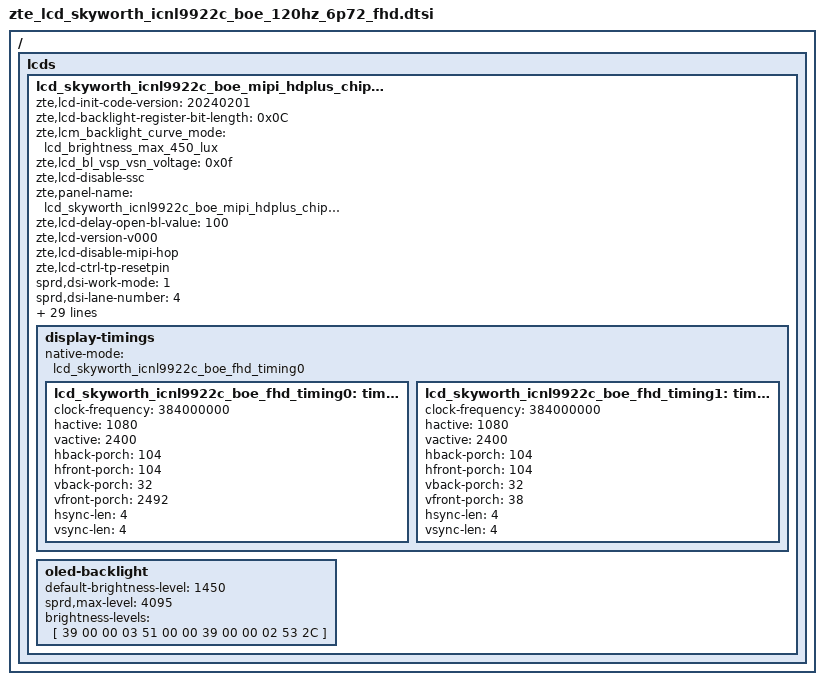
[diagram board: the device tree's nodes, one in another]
/ {
	fragment {
		target-path = "/";
		__overlay__ {
			lcds {
				lcd_skyworth_icnl9922c_boe_mipi_hdplus_chipone: lcd_skyworth_icnl9922c_boe_mipi_hdplus_chipone {
					zte,lcd-init-code-version = "20240201";

					zte,lcd-backlight-register-bit-length = <0x0C>;
					zte,lcm_backlight_curve_mode = "lcd_brightness_max_450_lux";
					zte,lcd_bl_vsp_vsn_voltage = <0x0f>;
					zte,lcd-disable-ssc;
					zte,panel-name = "lcd_skyworth_icnl9922c_boe_mipi_hdplus_chipone";
					zte,lcd-delay-open-bl-value = <100>;
					zte,lcd-version-v000;
					zte,lcd-disable-mipi-hop;
					zte,lcd-ctrl-tp-resetpin;

					sprd,dsi-work-mode = <1>;
					sprd,dsi-lane-number = <4>;
					sprd,dsi-color-format = "dsc";
					sprd,phy-bit-clock = <1100000>;
					sprd,phy-escape-clock = <20000>;/* kHz */

					sprd,width-mm = <70081>;
					sprd,height-mm = <155736>;
					sprd,vrr-enabled;
					sprd,vrr-max-layers = <3>;
					sprd,slice-width = <540>;
					sprd,slice-height = <8>;
					sprd,output-bpc = <8>;
					sprd,dsc-enable = <1>;
					sprd,dual-dsi-enable = <0>;

					sprd,esd-check-enable = <1>;/* 0:close , 1:open */
					sprd,esd-check-mode = <1>;/* 0:REG ,1:TE  */
					sprd,esd-check-period = <2000>;
					sprd,esd-check-register = <0x0A>;
					sprd,esd-check-value = <0x9C>;

					sprd,dphy-taget-val = <5>;

					sprd,reset-on-sequence = <1 5>, <0 15>, <1 25>;
					sprd,reset-off-sequence = <1 20>;

					sprd,use-gen-write;
					sprd,initial-command = [
39 00 00 04 F0 99 22 0C
39 00 00 10 70 C1 12 00 05 00 5A 00 6F 00 77 00 31 02 00 20
39 00 00 21 71 11 00 00 89 30 80 09 60 04 38 00 08 02 1C 02 1C 02 00 02 0E 00 20 00 BB 00 07 00 0C 0D B7 0C B7
39 00 00 21 72 18 00 10 F0 03 0C 20 00 06 0B 0B 33 0E 1C 2A 38 46 54 62 69 70 77 79 7B 7D 7E 01 02 01 00 09 40
39 00 00 19 73 09 BE 19 FC 19 FA 19 F8 1A 38 1A 78 1A B6 2A F6 2B 34 2B 74 3B 74 6B F4
39 00 00 1C C7 77 77 77 77 77 77 77 77 10 77 77 77 77 77 77 77 77 10 34 00 01 FF FF 00 F0 F0 00
39 00 00 21 80 FF F6 E8 DE D5 CE C8 C3 BE AE A2 99 91 89 83 79 6F 67 5F 5F 57 50 47 3F 39 34 2D 26 1D 11 0F 0D
39 00 00 21 81 FF F6 E8 DE D5 CE C8 C3 BE AE A2 99 91 89 83 79 6F 67 5F 5F 57 50 47 3F 39 34 2D 26 1D 11 0F 0D
39 00 00 21 82 FF F6 E8 DE D5 CE C8 C3 BE AE A2 99 91 89 83 79 6F 67 5F 5F 57 50 47 3F 39 34 2D 26 1D 11 0F 0D
39 00 00 21 83 09 0C 0A 08 05 03 02 0C 0A 08 05 03 02 0C 0A 08 05 03 02 12 0E 0A 06 02 00 12 0E 0A 06 02 00 12
39 00 00 21 84 0E 0A 06 02 00 04 E8 FC 3C E9 CC C8 37 02 30 4E 8F C3 CE 9C CC 83 70 23 04 E8 FC 3C E9 CC C8 37
39 00 00 1F 85 02 30 00 00 00 00 00 00 00 00 00 00 00 00 00 00 00 00 00 00 00 00 00 00 00 00 00 00 00 00
39 00 00 21 B2 0D 06 05 04 F2 22 03 00 22 00 00 00 00 00 00 00 00 63 5D 00 00 00 00 00 00 55 55 05 05 00 00 00
39 00 00 21 B3 31 0B 01 0B 81 63 00 00 5D 00 00 00 00 00 00 03 FC C0 00 C0 00 00 00 00 00 00 FF FF FF FF FF FF
39 00 00 21 B4 30 04 01 05 81 02 00 00 47 00 00 00 00 00 00 03 FC C0 00 C0 00 00 00 00 00 00 FF FF FF FF FF FF
39 00 00 21 B5 00 0B 06 0D 10 26 34 91 A2 33 44 00 26 00 BF 3C 02 08 20 30 00 00 00 00 00 00 00 00 00 00 5C 35
39 00 00 21 B6 82 82 82 1E 1D 1C 82 0D 0C 0F 0E 82 3A 3A 82 C0 82 00 00 00 28 05 04 01 FF FF FF 00 00 00 3C 00
39 00 00 21 B7 82 82 82 1E 1D 1C 82 0D 0C 0F 0E 82 3A 3A 82 C0 82 00 00 00 28 05 04 01 FF FF FF 00 00 00 3C 00
39 00 00 21 B8 03 01 01 82 00 80 00 00 00 00 1F 00 00 00 00 00 00 00 00 00 00 00 00 00 00 00 00 00 00 00 00 00
39 00 00 21 9D 00 00 00 12 1D 39 44 5E 54 61 6B 79 83 92 00 00 00 00 00 00 00 00 00 00 00 00 00 00 00 00 00 00
39 00 00 21 B9 12 33 21 12 33 21 12 33 21 12 33 21 12 33 21 12 33 21 12 33 21 12 33 21 00 00 00 00 00 00 00 02
39 00 00 1A BA 01 AB FB FE FB BF FF AB FB FE FB BF FF AB F8 02 0B 80 00 AB F8 02 0B 80 00
39 00 00 0F BB 01 02 03 0A 04 13 14 52 16 5C 00 15 16 00
39 00 00 21 BC 00 00 00 00 04 00 FF F8 0B 11 50 5E 55 99 00 00 00 00 00 00 00 00 00 00 00 00 00 00 00 00 00 00
39 00 00 0D BD A1 A2 52 2E 00 8F 0D 09 C1 04 01 AE
39 00 00 0D BE 28 1E 0B AA 43 35 33 32 1E 00 00 3A
39 00 00 17 C0 40 93 FF FF FF 3F FF 00 FF 00 CC 04 12 35 67 89 A0 FF FF F0 0B EB
39 00 00 16 C1 00 00 20 26 26 04 68 68 04 60 19 22 50 01 11 07 69 A0 A0 00 93
15 00 00 02 C2 00
39 00 00 21 C3 00 00 00 00 00 00 15 28 23 16 16 16 00 FF 40 40 2A 2A 2A 2A 2A 2A 2A 2A 00 00 18 00 00 10 00 00
39 00 00 21 C4 0C 93 A8 28 00 3C 02 00 00 0A 26 48 91 B3 75 00 F0 EF 00 00 00 00 00 00 00 00 00 00 00 00 00 00
39 00 00 21 C5 02 56 F0 A0 50 04 02 02 19 02 10 56 05 06 00 20 0D 0A 06 12 80 00 00 00 00 00 00 00 00 00 00 00
39 00 00 0D C6 67 08 18 48 48 20 3F 03 16 16 00 00
39 00 00 03 C8 06 09
39 00 00 21 C9 62 62 5C 5C 00 00 00 00 00 00 00 00 00 00 00 00 00 00 00 00 00 00 00 00 00 00 00 00 00 00 00 00
39 00 00 0C D0 0C 23 18 FF FF 00 80 0C FF 0F 40
39 00 00 0C 9A 11 7C 00 00 FF 00 0A 00 17 00 22
39 00 00 0B 99 91 B9 00 3F 00 7A 00 30 22 01
39 00 00 08 E0 0C 00 B0 10 00 15 7C
39 00 00 04 F0 00 00 00
39 00 00 03 35 00 00
39 00 00 03 51 00 00
39 00 00 03 53 2C 00
39 78 00 03 11 00 00
39 14 00 03 29 00 00
39 01 00 03 AC 05 00
					];

					zte,initial-command-fps120 = [
39 00 00 04 F0 99 22 0C
39 00 00 10 70 C1 12 00 05 00 5A 00 6F 00 77 00 31 02 00 20
39 00 00 21 71 11 00 00 89 30 80 09 60 04 38 00 08 02 1C 02 1C 02 00 02 0E 00 20 00 BB 00 07 00 0C 0D B7 0C B7
39 00 00 21 72 18 00 10 F0 03 0C 20 00 06 0B 0B 33 0E 1C 2A 38 46 54 62 69 70 77 79 7B 7D 7E 01 02 01 00 09 40
39 00 00 19 73 09 BE 19 FC 19 FA 19 F8 1A 38 1A 78 1A B6 2A F6 2B 34 2B 74 3B 74 6B F4
39 00 00 1C C7 77 77 77 77 77 77 77 77 10 77 77 77 77 77 77 77 77 10 34 00 01 FF FF 00 F0 F0 00
39 00 00 21 80 FF F6 E8 DE D5 CE C8 C3 BE AE A2 99 91 89 83 79 6F 67 5F 5F 57 50 47 3F 39 34 2D 26 1D 11 0F 0D
39 00 00 21 81 FF F6 E8 DE D5 CE C8 C3 BE AE A2 99 91 89 83 79 6F 67 5F 5F 57 50 47 3F 39 34 2D 26 1D 11 0F 0D
39 00 00 21 82 FF F6 E8 DE D5 CE C8 C3 BE AE A2 99 91 89 83 79 6F 67 5F 5F 57 50 47 3F 39 34 2D 26 1D 11 0F 0D
39 00 00 21 83 09 0C 0A 08 05 03 02 0C 0A 08 05 03 02 0C 0A 08 05 03 02 12 0E 0A 06 02 00 12 0E 0A 06 02 00 12
39 00 00 21 84 0E 0A 06 02 00 04 E8 FC 3C E9 CC C8 37 02 30 4E 8F C3 CE 9C CC 83 70 23 04 E8 FC 3C E9 CC C8 37
39 00 00 1F 85 02 30 00 00 00 00 00 00 00 00 00 00 00 00 00 00 00 00 00 00 00 00 00 00 00 00 00 00 00 00
39 00 00 21 B2 0D 06 05 04 F2 22 03 00 22 00 00 00 00 00 00 00 00 63 5D 00 00 00 00 00 00 55 55 05 05 00 00 00
39 00 00 21 B3 31 0B 01 0B 81 63 00 00 5D 00 00 00 00 00 00 03 FC C0 00 C0 00 00 00 00 00 00 FF FF FF FF FF FF
39 00 00 21 B4 30 04 01 05 81 02 00 00 47 00 00 00 00 00 00 03 FC C0 00 C0 00 00 00 00 00 00 FF FF FF FF FF FF
39 00 00 21 B5 00 0B 06 0D 10 26 34 91 A2 33 44 00 26 00 BF 3C 02 08 20 30 00 00 00 00 00 00 00 00 00 00 5C 35
39 00 00 21 B6 82 82 82 1E 1D 1C 82 0D 0C 0F 0E 82 3A 3A 82 C0 82 00 00 00 28 05 04 01 FF FF FF 00 00 00 3C 00
39 00 00 21 B7 82 82 82 1E 1D 1C 82 0D 0C 0F 0E 82 3A 3A 82 C0 82 00 00 00 28 05 04 01 FF FF FF 00 00 00 3C 00
39 00 00 21 B8 03 01 01 82 00 80 00 00 00 00 1F 00 00 00 00 00 00 00 00 00 00 00 00 00 00 00 00 00 00 00 00 00
39 00 00 21 9D 00 00 00 12 1D 39 44 5E 54 61 6B 79 83 92 00 00 00 00 00 00 00 00 00 00 00 00 00 00 00 00 00 00
39 00 00 21 B9 12 33 21 12 33 21 12 33 21 12 33 21 12 33 21 12 33 21 12 33 21 12 33 21 00 00 00 00 00 00 00 02
39 00 00 1A BA 01 AB FB FE FB BF FF AB FB FE FB BF FF AB F8 02 0B 80 00 AB F8 02 0B 80 00
39 00 00 0F BB 01 02 03 0A 04 13 14 52 16 5C 00 15 16 00
39 00 00 21 BC 00 00 00 00 04 00 FF F8 0B 11 50 5E 55 99 00 00 00 00 00 00 00 00 00 00 00 00 00 00 00 00 00 00
39 00 00 0D BD A1 A2 52 2E 00 8F 0D 09 C1 04 01 AE
39 00 00 0D BE 28 1E 0B AA 43 35 33 32 1E 00 00 3A
39 00 00 17 C0 40 93 FF FF FF 3F FF 00 FF 00 CC 04 12 35 67 89 A0 FF FF F0 0B EB
39 00 00 16 C1 00 00 20 26 26 04 68 68 04 60 19 22 50 01 11 07 69 A0 A0 00 93
15 00 00 02 C2 00
39 00 00 21 C3 00 00 00 00 00 00 15 28 23 16 16 16 00 FF 40 40 2A 2A 2A 2A 2A 2A 2A 2A 00 00 18 00 00 10 00 00
39 00 00 21 C4 0C 93 A8 28 00 3C 02 00 00 0A 26 48 91 B3 75 00 F0 EF 00 00 00 00 00 00 00 00 00 00 00 00 00 00
39 00 00 21 C5 02 56 F0 A0 50 04 02 02 19 02 10 56 05 06 00 20 0D 0A 06 12 80 00 00 00 00 00 00 00 00 00 00 00
39 00 00 0D C6 67 08 18 48 48 20 3F 03 16 16 00 00
39 00 00 03 C8 06 09
39 00 00 21 C9 62 62 5C 5C 00 00 00 00 00 00 00 00 00 00 00 00 00 00 00 00 00 00 00 00 00 00 00 00 00 00 00 00
39 00 00 0C D0 0C 23 18 FF FF 00 80 0C FF 0F 40
39 00 00 0C 9A 11 7C 00 00 FF 00 0A 00 17 00 22
39 00 00 0B 99 91 B9 00 3F 00 7A 00 30 22 01
39 00 00 08 E0 0C 00 B0 10 00 15 7C
39 00 00 04 F0 00 00 00
39 00 00 03 35 00 00
39 00 00 03 51 00 00
39 00 00 03 53 2C 00
39 78 00 03 11 00 00
39 14 00 03 29 00 00
39 01 00 03 AC 05 00
					];

					sprd,sleep-in-command = [
						39 00 00 04 F0 99 22 0C
						39 00 00 09 BB 01 02 03 0A 04 13 14 12
						39 00 00 04 F0 00 00 00
						39 00 00 03 AC 0A 00
						39 14 00 03 28 00 00
						39 78 00 03 10 00 00
						];
					sprd,sleep-out-command = [
						39 78 00 03 11 00 00
						39 14 00 03 29 00 00
						];
					display-timings {
						native-mode = <&lcd_skyworth_icnl9922c_boe_fhd_timing0>;
						lcd_skyworth_icnl9922c_boe_fhd_timing0: timing0 {
							clock-frequency = <384000000>;
							hactive = <1080>;
							vactive = <2400>;
							hback-porch = <104>;
							hfront-porch = <104>;
							vback-porch = <32>;
							vfront-porch = <2492>;
							hsync-len = <4>;
							vsync-len = <4>;
						};
						lcd_skyworth_icnl9922c_boe_fhd_timing1: timing1 {
							clock-frequency = <384000000>;
							hactive = <1080>;
							vactive = <2400>;
							hback-porch = <104>;
							hfront-porch = <104>;
							vback-porch = <32>;
							vfront-porch = <38>;
							hsync-len = <4>;
							vsync-len = <4>;
						};
					};
					oled-backlight {
						default-brightness-level = <1450>;
						sprd,max-level = <4095>;
						brightness-levels = [
							39 00 00 03 51 00 00
							39 00 00 02 53 2C
						];
					};
				};
			};
		};
	};
};
